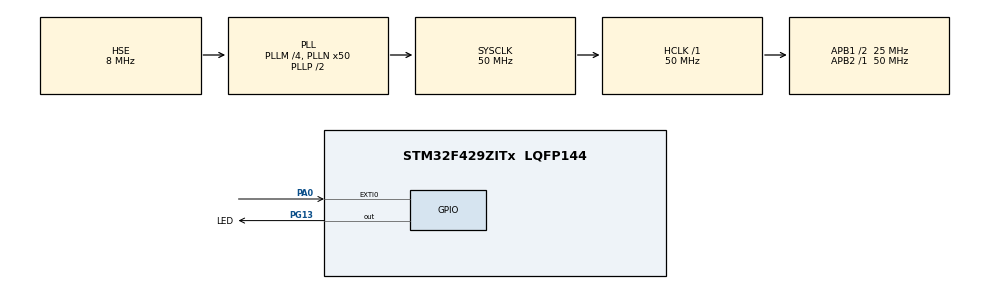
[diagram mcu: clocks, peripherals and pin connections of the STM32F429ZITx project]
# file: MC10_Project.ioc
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Mcu.Family=STM32F4
Mcu.Name=STM32F429ZITx
Mcu.Package=LQFP144
NVIC.EXTI0_IRQn=true\:0\:0\:false\:false\:true\:true\:true\:true
NVIC.PriorityGroup=NVIC_PRIORITYGROUP_4
NVIC.TIM8_TRG_COM_TIM14_IRQn=true\:0\:0\:false\:false\:true\:true\:true\:true
PA0/WKUP.GPIO_ModeDefaultEXTI=GPIO_MODE_IT_RISING
PA0/WKUP.GPIO_PuPd=GPIO_NOPULL
PA0/WKUP.Signal=GPXTI0
PA13.Mode=Serial_Wire
PA13.Signal=SYS_JTMS-SWDIO
PA14.Mode=Serial_Wire
PA14.Signal=SYS_JTCK-SWCLK
PC14/OSC32_IN.Mode=LSE-External-Oscillator
PC14/OSC32_IN.Signal=RCC_OSC32_IN
PC15/OSC32_OUT.Mode=LSE-External-Oscillator
PC15/OSC32_OUT.Signal=RCC_OSC32_OUT
PG13.GPIO_Label=LED
PG13.GPIO_PuPd=GPIO_NOPULL
PG13.GPIO_Speed=GPIO_SPEED_FREQ_VERY_HIGH
PG13.Signal=GPIO_Output
PH0/OSC_IN.Mode=HSE-External-Oscillator
PH0/OSC_IN.Signal=RCC_OSC_IN
PH1/OSC_OUT.Mode=HSE-External-Oscillator
PH1/OSC_OUT.Signal=RCC_OSC_OUT
ProjectManager.HeapSize=0x200
ProjectManager.StackSize=0x400
ProjectManager.TargetToolchain=STM32CubeIDE
RCC.48MHZClocksFreq_Value=33333333.333333332
RCC.AHBFreq_Value=50000000
RCC.APB1CLKDivider=RCC_HCLK_DIV2
RCC.APB1Freq_Value=25000000
RCC.APB1TimFreq_Value=50000000
RCC.APB2Freq_Value=50000000
RCC.APB2TimFreq_Value=50000000
RCC.CortexFreq_Value=50000000
RCC.HCLKFreq_Value=50000000
RCC.HSE_VALUE=8000000
RCC.HSI_VALUE=16000000
RCC.PLLM=4
RCC.PLLN=50
RCC.PLLQ=3
RCC.PLLSAIN=50
RCC.PLLSourceVirtual=RCC_PLLSOURCE_HSE
RCC.SYSCLKFreq_VALUE=50000000
RCC.SYSCLKSource=RCC_SYSCLKSOURCE_PLLCLK
RCC.VCOOutputFreq_Value=100000000
TIM14.Period=50000-1
TIM14.Prescaler=1000
VP_TIM14_VS_ClockSourceINT.Mode=Enable_Timer
board=STM32F429I-DISC1

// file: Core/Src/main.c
/* USER CODE BEGIN Header */
/**
  ******************************************************************************
  * @file           : main.c
  * @brief          : Main program body
  ******************************************************************************
  * @attention
  *
  * Copyright (c) 2025 STMicroelectronics.
  * All rights reserved.
  *
  * This software is licensed under terms that can be found in the LICENSE file
  * in the root directory of this software component.
  * If no LICENSE file comes with this software, it is provided AS-IS.
  *
  ******************************************************************************
  */
/* USER CODE END Header */
#include "main.h"
#include "tim.h"
#include "gpio.h"

/* USER CODE BEGIN PTD */
volatile uint8_t number_times_push_button = 0;
volatile uint32_t counterValue = 0;
/* USER CODE END PTD */

void SystemClock_Config(void);

int main(void)
{

  /* MCU Configuration--------------------------------------------------------*/

  /* Reset of all peripherals, Initializes the Flash interface and the Systick. */
  HAL_Init();

  /* Configure the system clock */
  SystemClock_Config();

  /* Initialize all configured peripherals */
  MX_GPIO_Init();
  MX_TIM14_Init();

  /* Infinite loop */
  while (1)
  {

    /* USER CODE BEGIN 3 */
	  switch(number_times_push_button){
	  case(0):
		HAL_TIM_Base_Stop(&htim14);
		HAL_TIM_Base_Start(&htim14);
		counterValue = __HAL_TIM_GET_COUNTER(&htim14);
		if(counterValue == 5000-1){
			__HAL_TIM_SET_COUNTER(&htim14, 0);    // Clear counter
			HAL_GPIO_TogglePin(GPIOG, GPIO_PIN_13);
		}
		break;
	  case(1):
			HAL_TIM_Base_Stop(&htim14);
			HAL_TIM_Base_Start(&htim14);
			counterValue = __HAL_TIM_GET_COUNTER(&htim14);
			if(counterValue == 10000-1){
				__HAL_TIM_SET_COUNTER(&htim14, 0);    // Clear counter
				HAL_GPIO_TogglePin(GPIOG, GPIO_PIN_13);
			}
			break;
	  case(2):
			HAL_TIM_Base_Stop(&htim14);
			HAL_TIM_Base_Start(&htim14);
			counterValue = __HAL_TIM_GET_COUNTER(&htim14);
			if(counterValue == 20000-1){
				__HAL_TIM_SET_COUNTER(&htim14, 0);    // Clear counter
				HAL_GPIO_TogglePin(GPIOG, GPIO_PIN_13);
			}
			break;
	  case(3):
			HAL_TIM_Base_Stop(&htim14);
			HAL_TIM_Base_Start(&htim14);
			counterValue = __HAL_TIM_GET_COUNTER(&htim14);
			if(counterValue == 49999){
				__HAL_TIM_SET_COUNTER(&htim14, 0);    // Clear counter
				HAL_GPIO_TogglePin(GPIOG, GPIO_PIN_13);
			}
			break;
	  default:
		  break;
	  }
  }
  /* USER CODE END 3 */
}

void SystemClock_Config(void)
{
  RCC_OscInitTypeDef RCC_OscInitStruct = {0};
  RCC_ClkInitTypeDef RCC_ClkInitStruct = {0};

  /** Configure the main internal regulator output voltage
  */
  __HAL_RCC_PWR_CLK_ENABLE();
  __HAL_PWR_VOLTAGESCALING_CONFIG(PWR_REGULATOR_VOLTAGE_SCALE3);

  /** Initializes the RCC Oscillators according to the specified parameters
  * in the RCC_OscInitTypeDef structure.
  */
  RCC_OscInitStruct.OscillatorType = RCC_OSCILLATORTYPE_HSE;
  RCC_OscInitStruct.HSEState = RCC_HSE_ON;
  RCC_OscInitStruct.PLL.PLLState = RCC_PLL_ON;
  RCC_OscInitStruct.PLL.PLLSource = RCC_PLLSOURCE_HSE;
  RCC_OscInitStruct.PLL.PLLM = 4;
  RCC_OscInitStruct.PLL.PLLN = 50;
  RCC_OscInitStruct.PLL.PLLP = RCC_PLLP_DIV2;
  RCC_OscInitStruct.PLL.PLLQ = 3;
  if (HAL_RCC_OscConfig(&RCC_OscInitStruct) != HAL_OK)
  {
    Error_Handler();
  }

  /** Initializes the CPU, AHB and APB buses clocks
  */
  RCC_ClkInitStruct.ClockType = RCC_CLOCKTYPE_HCLK|RCC_CLOCKTYPE_SYSCLK
                              |RCC_CLOCKTYPE_PCLK1|RCC_CLOCKTYPE_PCLK2;
  RCC_ClkInitStruct.SYSCLKSource = RCC_SYSCLKSOURCE_PLLCLK;
  RCC_ClkInitStruct.AHBCLKDivider = RCC_SYSCLK_DIV1;
  RCC_ClkInitStruct.APB1CLKDivider = RCC_HCLK_DIV2;
  RCC_ClkInitStruct.APB2CLKDivider = RCC_HCLK_DIV1;

  if (HAL_RCC_ClockConfig(&RCC_ClkInitStruct, FLASH_LATENCY_1) != HAL_OK)
  {
    Error_Handler();
  }
}

/* USER CODE BEGIN 4 */
void HAL_GPIO_EXTI_IRQHandler(uint16_t GPIO_Pin)
{
  /* EXTI line interrupt detected */
  if(__HAL_GPIO_EXTI_GET_IT(GPIO_Pin) != RESET)
  {
	  //HAL_TIM_Base_Start_IT(&tim14);
	  number_times_push_button++;
	  number_times_push_button = number_times_push_button%4;
	  /*
	  if(number_times_push_button%3==0){
		  HAL_GPIO_WritePin(GPIOG, GPIO_PIN_13, GPIO_PIN_SET);
	  }
	  else
		  HAL_GPIO_WritePin(GPIOG, GPIO_PIN_13, GPIO_PIN_RESET);*/
    __HAL_GPIO_EXTI_CLEAR_IT(GPIO_Pin);
    HAL_GPIO_EXTI_Callback(GPIO_Pin);
  }
}

HAL_TIM_PeriodElapsedCallback(TIM_HandleTypeDef *htim)
{
	//
}
/* USER CODE END 4 */

void Error_Handler(void)
{
  __disable_irq();
  while (1)
  {
  }
}
